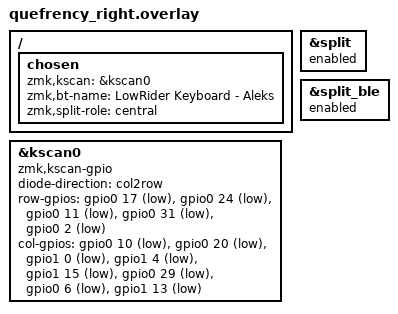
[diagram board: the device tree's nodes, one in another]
/ {
    chosen {
        zmk,kscan = &kscan0;
        zmk,bt-name = "LowRider Keyboard - Aleks";
        zmk,split-role = "central";
    };
};

&kscan0 {
    compatible = "zmk,kscan-gpio";
    diode-direction = "col2row";

    row-gpios = <&gpio0 17 (GPIO_ACTIVE_LOW)>,  // P0.17
                <&gpio0 24 (GPIO_ACTIVE_LOW)>,  // P0.24
                <&gpio0 11 (GPIO_ACTIVE_LOW)>,  // P0.11
                <&gpio0 31 (GPIO_ACTIVE_LOW)>,  // P0.31
                <&gpio0 2  (GPIO_ACTIVE_LOW)>;  // P0.02

    col-gpios = <&gpio0 10  (GPIO_ACTIVE_LOW)>,  // P0.10
                <&gpio0 20 (GPIO_ACTIVE_LOW)>,  // P0.20
                <&gpio1 0  (GPIO_ACTIVE_LOW)>,  // P1.00
                <&gpio1 4  (GPIO_ACTIVE_LOW)>,  // P1.04
                <&gpio1 15 (GPIO_ACTIVE_LOW)>,  // P1.15
                <&gpio0 29 (GPIO_ACTIVE_LOW)>,  // P0.29
                <&gpio0 6  (GPIO_ACTIVE_LOW)>,  // P0.06
                <&gpio1 13 (GPIO_ACTIVE_LOW)>;  // P1.13
};

&split {
    enabled;
};

&split_ble {
    enabled;
};
